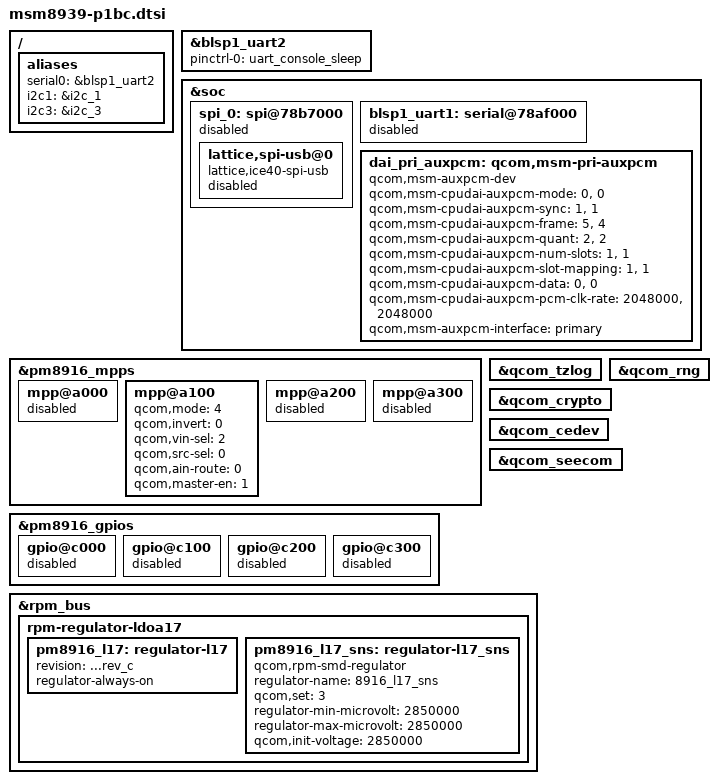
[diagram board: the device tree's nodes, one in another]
/* Copyright (c) 2014, The Linux Foundation. All rights reserved.
 *
 * This program is free software; you can redistribute it and/or modify
 * it under the terms of the GNU General Public License version 2 and
 * only version 2 as published by the Free Software Foundation.
 *
 * This program is distributed in the hope that it will be useful,
 * but WITHOUT ANY WARRANTY; without even the implied warranty of
 * MERCHANTABILITY or FITNESS FOR A PARTICULAR PURPOSE.  See the
 * GNU General Public License for more details.
 */


#include "msm8939-p1bc-pinctrl.dtsi"

/ {
	aliases {
		serial0 = &blsp1_uart2;
		i2c1 = &i2c_1; /* i2c_1 BLSP1 QUP1 */
		i2c3 = &i2c_3; /* i2c_3 BLSP1 QUP3 */
	};
};

&blsp1_uart2 {
	status = "ok";
	pinctrl-names = "default";
	pinctrl-0 = <&uart_console_sleep>;
};

&soc {
	spi_0: spi@78b7000 { /* BLSP1 QUP3 */
		status = "disabled";
		lattice,spi-usb@0 {
			compatible = "lattice,ice40-spi-usb";
			status = "disabled";
		};
	};
	blsp1_uart1: serial@78af000 {
		status = "disabled";
	};

	dai_pri_auxpcm: qcom,msm-pri-auxpcm {
	compatible = "qcom,msm-auxpcm-dev";
	qcom,msm-cpudai-auxpcm-mode = <0>, <0>;
	qcom,msm-cpudai-auxpcm-sync = <1>, <1>;
	qcom,msm-cpudai-auxpcm-frame = <5>, <4>;
	qcom,msm-cpudai-auxpcm-quant = <2>, <2>;
	qcom,msm-cpudai-auxpcm-num-slots = <1>, <1>;
	qcom,msm-cpudai-auxpcm-slot-mapping = <1>, <1>;
	qcom,msm-cpudai-auxpcm-data = <0>, <0>;
	qcom,msm-cpudai-auxpcm-pcm-clk-rate = <2048000>, <2048000>;
	qcom,msm-auxpcm-interface = "primary";
	};
};

&pm8916_mpps {
	mpp@a000 { /* MPP 1 */
		/* VDD_PX */
		status = "disabled";
	};

	mpp@a100 { /* MPP 2 */
		/* USB ID */
                status = "ok";
                qcom,mode = <4>;
                qcom,invert = <0>;
                qcom,vin-sel = <2>;
                qcom,src-sel = <0>;
                qcom,ain-route = <0>;
                qcom,master-en = <1>;
	};

	mpp@a200 { /* MPP 3 */
		/* VREF DAC */
		status = "disabled";
	};

	mpp@a300 { /* MPP 4 */
		/* HW Revision */
		status = "disabled";
	};
};

&pm8916_gpios {
	gpio@c000 { /* GPIO 1 */
		/* Battery UICC Alarm */
		status = "disabled";
	};

	gpio@c100 { /* GPIO 2 */
		status = "disabled";
	};

	gpio@c200 { /* GPIO 3 */
		/* External regulator control for WTR */
		status = "disabled";
	};

	gpio@c300 { /* GPIO 4 */
		/* External regulator control for APC */
		status = "disabled";
	};
};

&qcom_tzlog {
	status = "okay";
};

&qcom_rng {
	status = "okay";
};

&qcom_crypto {
	status = "okay";
};

&qcom_cedev {
	status = "okay";
};

&qcom_seecom {
	status = "okay";
};

&rpm_bus {
	rpm-regulator-ldoa17 {
		status = "ok";
		pm8916_l17: regulator-l17 {
			status = "ok";
			revision = "...rev_c";
			regulator-always-on;
		};

		pm8916_l17_sns: regulator-l17_sns {
			status = "ok";
			compatible = "qcom,rpm-smd-regulator";
			regulator-name = "8916_l17_sns";
			qcom,set = <3>;
			regulator-min-microvolt = <2850000>;
			regulator-max-microvolt = <2850000>;
			qcom,init-voltage = <2850000>;
		};
	};
};
#include "../msm8939-common.dtsi"
#include "msm8939-p1bc-panel.dtsi"
#include "msm8939-p1bc-sensor.dtsi"
#include "msm8939-p1bc-usb.dtsi"
#include "msm8939-p1bc-input.dtsi"
#include "msm8939-p1bc-misc.dtsi"
#include "msm8939-p1bc-pm.dtsi"
#include "msm8939-p1bc-camera.dtsi"
#include "msm8939-p1bc-connectivity.dtsi"
#include "msm8939-p1bc-sound.dtsi"
#include "msm8939-p1bc-nfc.dtsi"
